# RA register map
Vendor: Renesas; Series: All Chips; File version: x.xx
Registers are 32-bit, read-write, reset 0x0 unless marked. A register's access mark holds for its fields unless they carry their own. Offsets are from the block's base; [hi:lo] are bit positions; lines under a group give offsets from that group; {n}, {i} and the like mark numbered series; 'fields as' and 'values as' point back to an identical list.

## R_PMISC — I/O Ports-MISC
Base 0x40040D00
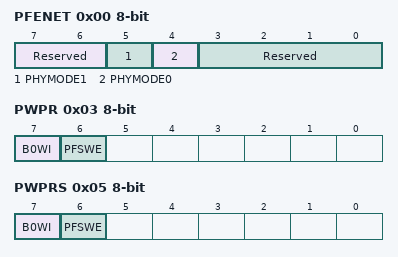
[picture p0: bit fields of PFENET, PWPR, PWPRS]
0x00 PFENET 8-bit — Ethernet Control Register
  [7:6] Reserved — These bits are read as 00. The write value should be 00.
  [5] PHYMODE1 — Ethernet Mode Setting ch1
    0=RMII mode (ETHERC channel 1); 1=MII mode (ETHERC channel 1)
  [4] PHYMODE0 — Ethernet Mode Setting ch0
    0=RMII mode (ETHERC channel 0); 1=MII mode (ETHERC channel 0)
  [3:0] Reserved — These bits are read as 0000. The write value should be 0000.
0x03 PWPR 8-bit reset not defined — Write-Protect Register
  [7] B0WI — PFSWE Bit Write Disable
    0=Writing to the PFSWE bit is enabled; other=Writing to the PFSWE bit is disabled
  [6] PFSWE — PmnPFS Register Write
    0=Writing to the PmnPFS register is disabled; 1=Writing to the PmnPFS register is enabled
0x05 PWPRS 8-bit reset not defined — Write-Protect Register for Secure
  fields as PWPR
{0x10+2i} PMSAR[{i}] (i=0..8) group — Port Security Attribution Register
  0x00 PMSAR 16-bit reset 0xFFFF — Port Security Attribution Register

## R_SRAM — SRAM
Base 0x40002000
0x00 PARIOAD 8-bit — SRAM Parity Error Operation After Detection Register
  [0] OAD — Operation after Detection
    1=Reset; 0=Non maskable interrupt
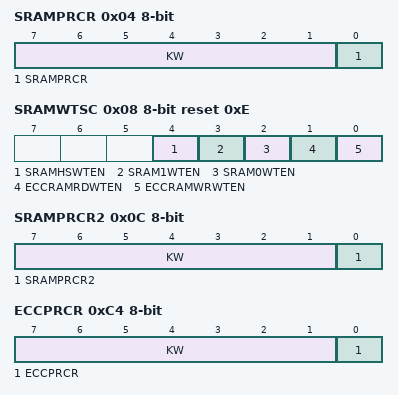
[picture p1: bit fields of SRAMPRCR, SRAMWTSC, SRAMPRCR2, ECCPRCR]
0x04 SRAMPRCR 8-bit — SRAM Protection Register
  [7:1] KW wo — Write Key Code
    120=Writing to the RAMPRCR bit is valid, when the KEY bits are written 1111000b; other=others (Writing to the RAMPRCR bit is invalid.)
  [0] SRAMPRCR — Register Write Control
    0=Disable writes to protected registers; 1=Enable writes to protected registers
0x08 SRAMWTSC 8-bit reset 0xE — RAM Wait State Control Register
  [4] SRAMHSWTEN — SRAMHS Wait Enable
    0=Not add wait state in read access cycle to SRAMHS; 1=Add wait state in read access cycle to SRAMHS
  [3] SRAM1WTEN — SRAM1 Wait Enable
    0=Not add wait state in read access cycle to SRAM1; 1=Add wait state in read access cycle to SRAM1
  [2] SRAM0WTEN — SRAM0 Wait Enable
    0=Not add wait state in read access cycle to SRAM0; 1=Add wait state in read access cycle to SRAM0
  [1] ECCRAMRDWTEN — ECCRAM Read wait enable
    0=Not add wait state in read access cycle to SRAM0 (ECC area); 1=Add wait state in read access cycle to SRAM0 (ECC area)
  [0] ECCRAMWRWTEN — ECCRAM Write Wait Enable
    0=Not add wait state in write access cycle to SRAM0 (ECC area); 1=Add wait state in write access cycle to SRAM0 (ECC area)
0x0C SRAMPRCR2 8-bit — SRAM Protection Register 2
  [7:1] KW wo — Write Key Code
  [0] SRAMPRCR2 — Register Write Control
    values as SRAMPRCR.SRAMPRCR
0xC0 ECCMODE 8-bit — ECC Operating Mode Control Register
  [1:0] ECCMOD — ECC Operating Mode Select
    0=Disable ECC function; 1=Setting prohibited; 2=Enable ECC function without error checking; 3=Enable ECC function with error checking
0xC1 ECC2STS 8-bit — ECC 2-Bit Error Status Register
  [0] ECC2ERR write-0-clears read-modifies — ECC 2-Bit Error Status
    0=No 2-bit ECC error occurred; 1=2-bit ECC error occurred
0xC2 ECC1STSEN 8-bit — ECC 1-Bit Error Information Update Enable Register
  [0] E1STSEN — ECC 1-Bit Error Information Update Enable
    0=Disables updating of the 1-bit ECC error information; 1=Enables updating of the 1-bit ECC error information
0xC3 ECC1STS 8-bit — ECC 1-Bit Error Status Register
  [0] ECC1ERR write-0-clears read-modifies — ECC 1-Bit Error Status
    0=No 1-bit ECC error occurred; 1=1-bit ECC error occurred
0xC4 ECCPRCR 8-bit — ECC Protection Register
  [7:1] KW wo — Write Key Code
    120=Writing to the ECCRAMPRCR bit is valid, when the KEY bits are written 1111000b; other=others (Writing to the ECCRAMPRCR bit is invalid.)
  [0] ECCPRCR — Register Write Control
    0=Disable writes to the protected registers; 1=Enable writes to the protected registers
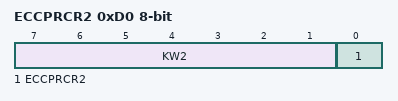
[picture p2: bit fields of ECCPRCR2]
0xD0 ECCPRCR2 8-bit — ECC Protection Register 2
  [7:1] KW2 wo — Write Key Code
    120=These bits enable or disable writes to the ECCPRCR2 bit; other=others (Writing to the ECCRAMPRCR2 bit is invalid.)
  [0] ECCPRCR2 — Register Write Control
    values as ECCPRCR.ECCPRCR
0xD4 ECCETST 8-bit — ECC Test Control Register
  [0] TSTBYP — ECC Bypass Select
    0=ECC bypass disabled; 1=ECC bypass enabled
0xD8 ECCOAD 8-bit — SRAM ECC Error Operation After Detection Register
  [0] OAD — Operation after Detection
    0=Non-maskable interrupt; 1=Reset

## R_TSN — Temperature Sensor
Base 0x407EC000
0x228 TSCDRL 8-bit ro reset not defined — Temperature Sensor Calibration Data Register L
  [7:0] TSCDRL — The calibration data stores the lower 8 bits of the convertedvalue.
0x229 TSCDRH 8-bit ro reset not defined — Temperature Sensor Calibration Data Register H
  [7:0] TSCDRH — The calibration data stores the higher 8 bits of the convertedvalue.

## R_TSN_CAL — Temperature Sensor
Base 0x407FB17C
0x00 TSCDR ro reset not defined — Temperature Sensor 32 bit Calibration Data Register
  [31:0] TSCDR — The 32 bit TSCDR register stores temperature sensor calibration converted value.

## R_TSN_CTRL — Temperature Sensor
Base 0x4005D000
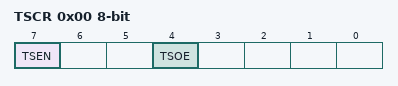
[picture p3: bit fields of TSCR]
0x00 TSCR 8-bit — Temperature Sensor Control Register
  [7] TSEN — Temperature Sensor Output Enable
    0=Stops the temperature sensor; 1=Starts the temperature sensor
  [4] TSOE — Temperature Sensor Enable
    0=Disables output from the temperature sensor to the 12-bit A/D converter; 1=Enables output from the temperature sensor to the 12-bit A/D converter

## R_WDT — Watchdog Timer
Base 0x40044200
0x00 WDTRR 8-bit reset 0xFF — WDT Refresh Register
  [7:0] WDTRR — WDTRR is an 8-bit register that refreshes the down-counter of the WDT.
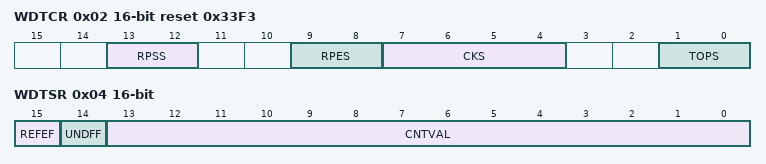
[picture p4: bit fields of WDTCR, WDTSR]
0x02 WDTCR 16-bit reset 0x33F3 — WDT Control Register
  [13:12] RPSS — Window Start Position Selection
    0=25%; 1=50%; 2=75%; 3=100% (window start position is not specified)
  [9:8] RPES — Window End Position Selection
    0=75%; 1=50%; 2=25%; 3=0% (window end position is not specified)
  [7:4] CKS — Clock Division Ratio Selection
    1=PCLK/4; 4=PCLK/64; 15=PCLK/128; 6=PCLK/512; 7=PCLK/2048; 8=PCLK/8192; other=others (setting prohibited)
  [1:0] TOPS — Timeout Period Selection
    0=1,024 cycles (03FFh); 1=4,096 cycles (0FFFh); 2=8,192 cycles (1FFFh); 3=16,384 cycles (3FFFh)
0x04 WDTSR 16-bit — WDT Status Register
  [15] REFEF write-0-clears read-modifies — Refresh Error Flag
    0=No refresh error occurred; 1=Refresh error occurred
  [14] UNDFF write-0-clears read-modifies — Underflow Flag
    0=No underflow occurred; 1=Underflow occurred
  [13:0] CNTVAL ro — Down-Counter Value
0x06 WDTRCR 8-bit reset 0x80 — WDT Reset Control Register
  [7] RSTIRQS — Reset Interrupt Request Selection
    0=Non-maskable interrupt request or interrupt request output is enabled; 1=Reset output is enabled
0x08 WDTCSTPR 8-bit reset 0x80 — WDT Count Stop Control Register
  [7] SLCSTP — Sleep-Mode Count Stop Control
    0=Count stop is disabled; 1=Count is stopped at a transition to sleep mode

## R_TZF — TrustZone Filter
Base 0x40000E00
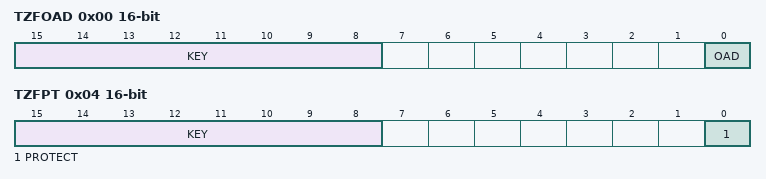
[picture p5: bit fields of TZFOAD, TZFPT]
0x00 TZFOAD 16-bit — TrustZone Filter Operation After Detection Register
  [15:8] KEY wo — KeyCode
  [0] OAD — Operation after detection
    0=Reset; 1=Non-maskable interrupt
0x04 TZFPT 16-bit — TrustZone Filter Protect Register
  [15:8] KEY wo — KeyCode
  [0] PROTECT — Protection of register
    0=All Bus TrustZone Filter register writing is protected. Read is possible.; 1=All Bus TrustZone Filter register writing is possible
0x180 TZFSAR reset 0xFFFFFFFF — TrustZone Filter Security Attribution Register
  [0] TZFSA0 — Security attributes of registers for TrustZone Filter
    0=Secure; 1=Non-secure
